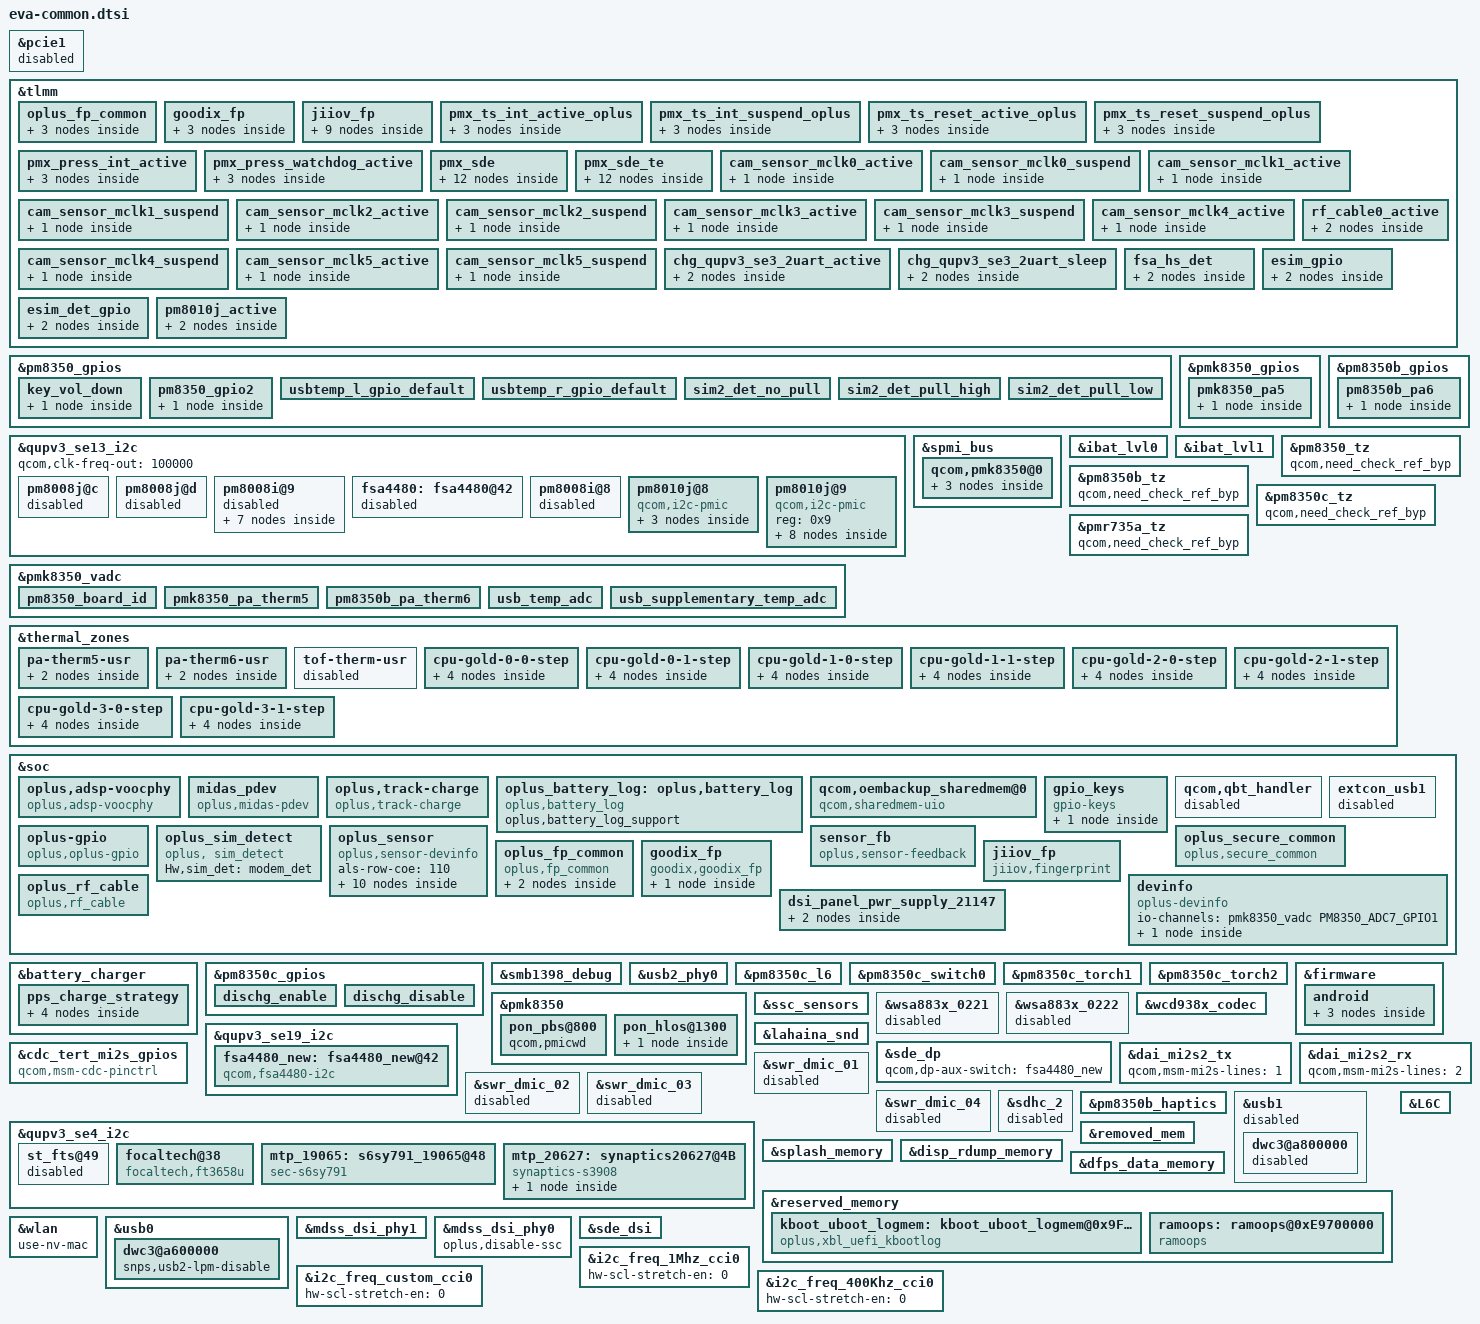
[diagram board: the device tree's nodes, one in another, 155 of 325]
//lahaina-pcie.dtsi
&pcie1 {
		status = "disabled";
		//#endif
};



//lahaina-pinctrl.dtsi

&tlmm {
	//#ifdef OPLUS_FEATURE_FINGERPRINT
	oplus_fp_common{
		gpio_id2_default: gpio_id2_default {
			mux {
				pins = "gpio119";
				function = "gpio";
			};
			config {
				pins = "gpio119";
				drive-strength = <2>;
				bias-pull-up;
				input-enable;
			};
		};
	};
	goodix_fp{
		gpio_goodix_irq_default: gpio_goodix_irq_default {
			mux {
				pins = "gpio38";
				function = "gpio";
			};
			config {
				pins = "gpio38";
				drive-strength = <2>;
				bias-disable;
				input-enable;
			};
		};
	};
	
	jiiov_fp{
		gpio_anc_reset_reset: gpio_anc_reset_reset {
			mux {
				pins = "gpio28";
				function = "gpio";
			};
			config {
				pins = "gpio28";
				drive-strength = <2>;
				bias-disable;
				output-low;
			};
		};
		gpio_anc_reset_active: gpio_anc_reset_active {
			mux {
				pins = "gpio28";
				function = "gpio";
			};
			config {
				pins = "gpio28";
				drive-strength = <2>;
				bias-disable;
				output-high;
			};
		};
		gpio_anc_irq_active: gpio_anc_irq_active {
			mux {
				pins = "gpio38";
				function = "gpio";
			};
			config {
				pins = "gpio38";
				drive-strength = <2>;
				bias-pull-down;
			};
		};
	};
	//#endif /*OPLUS_FEATURE_FINGERPRINT*/

	/* add pingrp for touchscreen */
	pmx_ts_int_active_oplus {
		ts_int_active: ts_int_active {
			mux {
				pins = "gpio23";
				function = "gpio";
			};

			config {
				pins = "gpio23";
				drive-strength = <8>;
				bias-disable;
				input-enable;
			};
		};
	};

	pmx_ts_int_suspend_oplus {
		ts_int_suspend1: ts_int_suspend1 {
			mux {
				pins = "gpio23";
				function = "gpio";
			};

			config {
				pins = "gpio23";
				drive-strength = <8>;
				//bias-pull-down;
				bias-pull-up;
				input-enable;
			};
		};
	};

	pmx_ts_reset_active_oplus {
		ts_reset_active: ts_reset_active {
			mux {
				pins = "gpio22";
				function = "gpio";
			};

			config {
				pins = "gpio22";
				drive-strength = <8>;
				output-low;
				bias-disable;
			};
		};
	};

	pmx_ts_reset_suspend_oplus {
		ts_reset_suspend1: ts_reset_suspend1 {
			mux {
				pins = "gpio22";
				function = "gpio";
			};

			config {
				pins = "gpio22";
				drive-strength = <2>;
				bias-pull-down;
			};
		};
	};
	//#endif


	pmx_press_int_active {
		press_int_active: press_int_active {
			mux {
				pins = "gpio51";
				function = "gpio";
			};

			config {
				pins = "gpio51";
				drive-strength = <2>;
				bias-disable;
				input-enable;
			};
		};
	};

	pmx_press_watchdog_active {
		watchdog_active: watchdog_active {
			mux {
				pins = "gpio97";
				function = "gpio";
			};

			config {
				pins = "gpio97";
				drive-strength = <2>;
				bias-disable;
				output-high;
			};
		};
	};
	//#endif

	pmx_sde: pmx_sde {
		sde_dsi_active: sde_dsi_active {
			mux {
				pins = "gpio24";
				function = "gpio";
			};

			config {
				pins = "gpio24";
				drive-strength = <8>;   /* 8 mA */
				bias-disable = <0>;   /* no pull */
			};
		};

		sde_dsi_suspend: sde_dsi_suspend {
			mux {
				pins = "gpio24";
				function = "gpio";
			};

			config {
				pins = "gpio24";
				drive-strength = <2>;   /* 2 mA */
				bias-pull-down;         /* PULL DOWN */
			};
		};

		sde_dsi1_active: sde_dsi1_active {
			mux {
				pins = "gpio25";
				function = "gpio";
			};

			config {
				pins = "gpio25";
				drive-strength = <8>;   /* 8 mA */
				bias-disable = <0>;   /* no pull */
			};
		};

		sde_dsi1_suspend: sde_dsi1_suspend {
			mux {
				pins = "gpio25";
				function = "gpio";
			};

			config {
				pins = "gpio25";
				drive-strength = <2>;   /* 2 mA */
				bias-pull-down;         /* PULL DOWN */
			};
		};
	};

	pmx_sde_te: pmx_sde_te {
		sde_te_active: sde_te_active {
			mux {
				pins = "gpio82";
				function = "mdp_vsync";
			};

			config {
				pins = "gpio82";
				drive-strength = <2>;   /* 2 mA */
				bias-pull-down;         /* PULL DOWN */
			};
		};

		sde_te_suspend: sde_te_suspend {
			mux {
				pins = "gpio82";
				function = "mdp_vsync";
			};

			config {
				pins = "gpio82";
				drive-strength = <2>;   /* 2 mA */
				bias-pull-down;         /* PULL DOWN */
			};
		};

		sde_te1_active: sde_te1_active {
			mux {
				pins = "gpio83";
				function = "mdp_vsync";
			};

			config {
				pins = "gpio83";
				drive-strength = <2>;   /* 2 mA */
				bias-pull-down;         /* PULL DOWN */
			};
		};

		sde_te1_suspend: sde_te1_suspend {
			mux {
				pins = "gpio83";
				function = "mdp_vsync";
			};

			config {
				pins = "gpio83";
				drive-strength = <2>;   /* 2 mA */
				bias-pull-down;         /* PULL DOWN */
			};
		};
	};
	//#endif
	cam_sensor_mclk0_active {

		config {
			/* #ifdef OPLUS_FEATURE_CAMERA_COMMON */
			drive-strength = <4>; /* 6 MA */
			/* #else */
			// drive-strength = <2>; /* 2 MA */
			/* #endif */
		};
	};
	cam_sensor_mclk0_suspend {

		config {
			/* #ifdef OPLUS_FEATURE_CAMERA_COMMON */
			drive-strength = <4>; /* 6 MA */
			/* #else */
			// drive-strength = <2>; /* 2 MA */
			/* #endif */
		};
	};

	cam_sensor_mclk1_active {

		config {
			/* #ifdef OPLUS_FEATURE_CAMERA_COMMON */
			drive-strength = <4>; /* 4 MA */
			/* #else */
			// drive-strength = <2>; /* 2 MA */
			/* #endif */
		};
	};


	cam_sensor_mclk1_suspend {

		config {
			/* #ifdef OPLUS_FEATURE_CAMERA_COMMON */
			drive-strength = <4>; /* 4 MA */
			/* #else */
			// drive-strength = <2>; /* 2 MA */
			/* #endif */
		};
	};

	cam_sensor_mclk2_active {

		config {
			/* #ifdef OPLUS_FEATURE_CAMERA_COMMON */
			drive-strength = <6>; /* 6 MA */
			/* #else */
			// drive-strength = <2>; /* 2 MA */
			/* #endif */
		};
	};

	cam_sensor_mclk2_suspend {

		config {
			/* #ifdef OPLUS_FEATURE_CAMERA_COMMON */
			drive-strength = <6>; /* 6 MA */
			/* #else */
			// drive-strength = <2>; /* 2 MA */
			/* #endif */
		};
	};

	cam_sensor_mclk3_active {

		config {
			/* #ifdef OPLUS_FEATURE_CAMERA_COMMON */
			drive-strength = <6>; /* 6 MA */
			/* #else */
			// drive-strength = <2>; /* 2 MA */
			/* #endif */
		};
	};

	cam_sensor_mclk3_suspend {

		config {
			/* #ifdef OPLUS_FEATURE_CAMERA_COMMON */
			drive-strength = <6>; /* 6 MA */
			/* #else */
			// drive-strength = <2>; /* 2 MA */
			/* #endif */
		};
	};

	cam_sensor_mclk4_active {

		config {
			/* #ifdef OPLUS_FEATURE_CAMERA_COMMON */
			drive-strength = <6>; /* 6 MA */
			/* #else */
			// drive-strength = <2>; /* 2 MA */
			/* #endif */
		};
	};

	cam_sensor_mclk4_suspend {

		config {
			/* #ifdef OPLUS_FEATURE_CAMERA_COMMON */
			drive-strength = <6>; /* 6 MA */
			/* #else */
			// drive-strength = <2>; /* 2 MA */
			/* #endif */
		};
	};

	cam_sensor_mclk5_active {

		config {
			/* #ifdef OPLUS_FEATURE_CAMERA_COMMON */
			drive-strength = <6>; /* 6 MA */
			/* #else */
			// drive-strength = <2>; /* 2 MA */
			/* #endif */
		};
	};

	cam_sensor_mclk5_suspend {

		config {
			/* #ifdef OPLUS_FEATURE_CAMERA_COMMON */
			drive-strength = <6>; /* 6 MA */
			/* #else */
			// drive-strength = <2>; /* 2 MA */
			/* #endif */
		};
	};

	rf_cable0_active: rf_cable0_active {
		mux {
			pins = "gpio99";
			function = "gpio";
		};
		config {
			pins = "gpio99";
			drive-strength = <2>;
			input-enable;
			bias-pull-up;
		};
	};
};



//lahaina-pmic-overlay.dtsi
&pm8350_gpios {
	///delete-node/ key_vol_up;
//#else
	key_vol_down {
		key_vol_down_default: key_vol_down_default {
			pins = "gpio6";
			function = "normal";
			input-enable;
			bias-pull-up;
			power-source = <1>;
		};
	};
//#endif
};

&qupv3_se13_i2c {
	pm8008j@c {
		status = "disabled";
	};

	pm8008j@d {
		status = "disabled";
	};

	pm8008i@9 {

		qcom,pm8008i-regulator {
			vdd_l3_l4-supply = <&BOB>;
			//vdd_l3_l4-supply = <&S1C>;
			vdd_l5-supply = <&BOB>;
/*endif*/


			//L2I: pm8008i_l2: regulator@4100 {
			regulator@4100 {
				reg = <0x4100>;
				regulator-name = "pm8008i_l2";
				regulator-min-microvolt = <944000>;
				regulator-max-microvolt = <1256000>;
/*endif*/
				qcom,min-dropout-voltage = <150000>;
				qcom,hpm-min-load = <30000>;
			};

			//L3I: pm8008i_l3: regulator@4200 {
			regulator@4200 {
				reg = <0x4200>;
				regulator-name = "pm8008i_l3";
				regulator-min-microvolt = <1500000>;
				//regulator-min-microvolt = <1696000>;
				regulator-max-microvolt = <1800000>;
				qcom,min-dropout-voltage = <70000>;
/*endif*/
			};

			//L4I: pm8008i_l4: regulator@4300 {
			regulator@4300 {
				reg = <0x4300>;
				regulator-name = "pm8008i_l4";
				regulator-min-microvolt = <1696000>;
				regulator-max-microvolt = <1800000>;
				qcom,min-dropout-voltage = <70000>;
/*endif*/
			};

			//L5I: pm8008i_l5: regulator@4400 {
			regulator@4400 {
				reg = <0x4400>;
				regulator-name = "pm8008i_l5";
				regulator-min-microvolt = <2696000>;
				regulator-max-microvolt = <3000000>;
				qcom,min-dropout-voltage = <200000>;
/*endif*/
			};

			//L6I: pm8008i_l6: regulator@4500 {
			regulator@4500 {
				reg = <0x4500>;
				regulator-name = "pm8008i_l6";
				regulator-min-microvolt = <2696000>;
				regulator-max-microvolt = <3000000>;
/*endif*/
				qcom,min-dropout-voltage = <200000>;
			};

			//L7I: pm8008i_l7: regulator@4600 {
			regulator@4600 {
				reg = <0x4600>;
				regulator-name = "pm8008i_l7";
				regulator-min-microvolt = <2696000>;
				regulator-max-microvolt = <3000000>;
				qcom,min-dropout-voltage = <200000>;
			};
		};
	};

};



&pm8350_gpios {

	pm8350_gpio2 {
		pm8350_gpio2_default: pm8350_gpio2_default {
			pins = "gpio2";
			bias-high-impedance;
		};
	};
};

&pmk8350_gpios {
	pmk8350_pa5 {
		pmk8350_pa5_therm_default: pmk8350_pa5_therm_default {
			pins = "gpio3";
			bias-high-impedance;
		};
	};

};

&pm8350b_gpios {
	pm8350b_pa6 {
		pm8350b_pa6_therm_default: pm8350b_pa6_therm_default {
			pins = "gpio1";
			bias-high-impedance;
		};
	};

};

&spmi_bus {
	qcom,pmk8350@0 {
		pm8350_adc_tm_iio: adc_tm_iio@3400 {
			/* Alternate ADC_TM DT node */
			compatible = "qcom,adc-tm7-iio";
			/* With this entry, a feature-reduced
			version of the driver is initialized (only
			thermistor reads, no interrupt functionality
			for exposed thermistors) */
			reg = <0x3400>;
			#thermal-sensor-cells = <1>;
			#address-cells = <1>;
			#size-cells = <0>;
			io-channels = <&pmk8350_vadc PM8350B_ADC7_GPIO1_100K_PU>,
				      <&pmk8350_vadc PMK8350_ADC7_AMUX_THM4_100K_PU>;
			/* Similar to io-channels in actual ADC_TM node,
			for reading thermistor temperature from
			VADC */

			pm8350b_pa_therm6 {
				/* ADC_TM child node, similar to previous */
				reg = <PM8350B_ADC7_GPIO1_100K_PU>;
				qcom,ratiometric;
				qcom,hw-settle-time = <200>;
			};
			pmk8350_pa_therm5 {
				/* ADC_TM child node, similar to previous */
				reg = <PMK8350_ADC7_AMUX_THM4_100K_PU>;
				qcom,ratiometric;
				qcom,hw-settle-time = <200>;
			};

		};
	};
};

&pmk8350_vadc {
	pinctrl-names = "default";
	//pinctrl-0 = <&pm8350_rear_tof_therm_default>;
//#else
	pinctrl-0 = <&pm8350_gpio2_default &pmk8350_pa5_therm_default &pm8350b_pa6_therm_default>;

	pm8350_board_id {
		reg = <PM8350_ADC7_GPIO1>;
		label = "pm8350_board_id";
		//qcom,ratiometric;
		qcom,hw-settle-time = <200>;
		qcom,pre-scaling = <1 1>;
	};

	pmk8350_pa_therm5 {
		reg = <PMK8350_ADC7_AMUX_THM4_100K_PU>;
		label = "pmk8350_pa_therm5";
		qcom,ratiometric;
		qcom,hw-settle-time = <200>;
		qcom,pre-scaling = <1 1>;
	};

	pm8350b_pa_therm6 {
		reg = <PM8350B_ADC7_GPIO1_100K_PU>;
		label = "pm8350b_pa_therm6";
		qcom,ratiometric;
		qcom,hw-settle-time = <200>;
		qcom,pre-scaling = <1 1>;
	};
};

&ibat_lvl0 {
	temperature = <7500>;
	hysteresis = <200>;
	type = "passive";
};
&ibat_lvl1 {
	temperature = <10000>;
	hysteresis = <200>;
	type = "passive";
};

//#ifdef OPLUS_FEATURE_CHG_BASIC
&pm8350_tz {
	qcom,need_check_ref_byp;
};

&pm8350b_tz {
	qcom,need_check_ref_byp;
};

&pm8350c_tz {
	qcom,need_check_ref_byp;
};

&pmr735a_tz {
	qcom,need_check_ref_byp;
};
//#endif

&thermal_zones {
	pa-therm5-usr {
		polling-delay-passive = <0>;
		polling-delay = <0>;
		thermal-governor = "user_space";
		thermal-sensors = <&pm8350_adc_tm_iio PMK8350_ADC7_AMUX_THM4_100K_PU>;
		/* phandle and channel number of added channel */
		wake-capable-sensor;
		trips {
			active-config0 {
				temperature = <55000>;
				hysteresis = <1000>;
				type = "passive";
			};
		};
	};

	pa-therm6-usr {
		polling-delay-passive = <0>;
		polling-delay = <0>;
		thermal-governor = "user_space";
		thermal-sensors = <&pm8350_adc_tm_iio PM8350B_ADC7_GPIO1_100K_PU>;
		/* phandle and channel number of added channel */
		wake-capable-sensor;
		trips {
			active-config0 {
				temperature = <55000>;
				hysteresis = <1000>;
				type = "passive";
			};
		};
	};
};

&soc {
	oplus,adsp-voocphy {
		compatible = "oplus,adsp-voocphy";
	};

	midas_pdev {
                compatible = "oplus,midas-pdev";
        };
};
&battery_charger {
	//for oplus chg framework:
	oplus,chg_ops = "plat-pmic";
	qcom,smart_charging_screenoff;
	qcom,input_current_charger_ma = <2000>;
	qcom,pd_input_current_charger_ma = <2000>;
	qcom,qc_input_current_charger_ma = <2000>;

	qcom,input_current_usb_ma = <500>;

	qcom,input_current_cdp_ma = <1500>;
	qcom,input_current_led_ma = <1200>;
	qcom,input_current_led_ma_high = <1800>;
	qcom,input_current_led_ma_warm = <1800>;
	qcom,input_current_led_ma_normal = <2000>;
	qcom,led_warm_bat_decidegc = <350>;
	qcom,led_high_bat_decidegc = <370>;

	qcom,input_current_camera_ma = <1200>;

	qcom,input_current_vooc_led_ma_high = <1800>;
	qcom,input_current_vooc_led_ma_warm = <1800>;
	qcom,input_current_vooc_led_ma_normal = <3600>;
	qcom,input_current_vooc_ma_normal = <3600>;
	qcom,vooc_temp_bat_normal_decidegc = <350>;
	qcom,input_current_vooc_ma_warm = <3200>;
	qcom,vooc_temp_bat_warm_decidegc = <370>;
	qcom,input_current_vooc_ma_high = <2200>;
	qcom,vooc_temp_bat_hot_decidegc = <440>;

	qcom,charger_current_vooc_ma_normal = <1800>;

	qcom,chg_ctrl_by_calling;
	qcom,input_current_calling_ma = <1500>;

	//qcom,input_current_led_ma_overtemp = <900>;
	qcom,overtemp_bat_decidegc = <350>;
	qcom,iterm_disabled = <0>;
	qcom,iterm_ma = <130>;
	qcom,recharge-mv = <100>;
	qcom,batt_capacity_mah = <5000>;/*typical capacity*/
	//qcom,batt_capacity_mah = <4400>; /*rated capacity*/

	qcom,removed_bat_decidegc = <190>;  /*<-19C*/

	qcom,cold_bat_decidegc = <100>;  /*-10C~0C*/
	qcom,temp_cold_vfloat_mv = <4435>;
	qcom,temp_cold_fastchg_current_ma = <600>;

	qcom,little_cold_bat_decidegc = <0>;	/*0C~5C*/
	qcom,temp_little_cold_vfloat_mv = <4435>;
	qcom,temp_little_cold_fastchg_current_ma_high = <1100>;
	qcom,temp_little_cold_fastchg_current_ma_low = <1100>;
	qcom,temp_little_cold_fastchg_current_ma = <1100>;
	qcom,pd_temp_little_cold_fastchg_current_ma_high = <2000>;
	qcom,pd_temp_little_cold_fastchg_current_ma_low = <1560>;
	qcom,qc_temp_little_cold_fastchg_current_ma_high = <2000>;
	qcom,qc_temp_little_cold_fastchg_current_ma_low = <1560>;

	qcom,cool_bat_decidegc = <50>;	/*5C~12C*/
	qcom,temp_cool_vfloat_mv = <4435>;
	qcom,temp_cool_fastchg_current_ma_high = <1100>;
	qcom,temp_cool_fastchg_current_ma_low = <1100>;
	qcom,pd_temp_cool_fastchg_current_ma_high = <2000>;
	qcom,pd_temp_cool_fastchg_current_ma_low = <2000>;
	qcom,qc_temp_cool_fastchg_current_ma_high = <2000>;
	qcom,qc_temp_cool_fastchg_current_ma_low = <2000>;

	qcom,little_cool_bat_decidegc = <120>;	/*12C~16C*/
	qcom,temp_little_cool_vfloat_mv = <4435>;
	qcom,temp_little_cool_fastchg_current_ma = <1100>;
	qcom,pd_temp_little_cool_fastchg_current_ma = <2000>;
	qcom,qc_temp_little_cool_fastchg_current_ma = <2000>;

	qcom,normal_bat_decidegc = <160>;	/*16C~44C*/
	qcom,temp_normal_fastchg_current_ma = <1100>;
	qcom,temp_normal_vfloat_mv = <4435>;
	qcom,pd_temp_normal_fastchg_current_ma = <2000>;
	qcom,qc_temp_normal_fastchg_current_ma = <2000>;

	qcom,warm_bat_decidegc = <450>;		/*45C~53C*/ /*8pin Bat Vooc project need add 3 degree C*/
	qcom,temp_warm_vfloat_mv = <4130>;
	qcom,temp_warm_fastchg_current_ma = <1100>;
	qcom,pd_temp_warm_fastchg_current_ma = <1200>;
	qcom,qc_temp_warm_fastchg_current_ma = <1200>;
	qcom,temp_warm_fastchg_current_ma_led_on = <500>;

	qcom,hot_bat_decidegc = <530>;

	qcom,non_standard_vfloat_mv = <3980>;
	qcom,non_standard_fastchg_current_ma = <512>;

	qcom,short_c_bat_cv_mv = <4330>;
	qcom,short_c_bat_vfloat_mv = <3800>;
	qcom,short_c_bat_fastchg_current_ma = <512>;

	qcom,cold_vfloat_sw_limit = <4385>;
	qcom,little_cold_vfloat_sw_limit = <4385>;
	qcom,cool_vfloat_sw_limit = <4385>;
	qcom,little_cool_vfloat_sw_limit = <4385>;
	qcom,normal_vfloat_sw_limit = <4385>;
	qcom,warm_vfloat_sw_limit = <4080>;
	qcom,non_standard_vfloat_sw_limit = <3930>;
	qcom,short_c_bat_vfloat_sw_limit = <3750>;

	qcom,max_chg_time_sec = <36000>;
	qcom,charger_hv_thr = <9900>;
	qcom,charger_recv_thr = <9500>;
	qcom,charger_lv_thr = <3400>;
	qcom,vbatt_full_thr = <4435>;
	qcom,vbatt_hv_thr = <4600>;
	qcom,vfloat_step_mv = <8>;
	qcom,non_standard_vfloat_over_sw_limit = <3990>;
	qcom,cold_vfloat_over_sw_limit = <4445>;
	qcom,little_cold_vfloat_over_sw_limit = <4445>;
	qcom,cool_vfloat_over_sw_limit = <4445>;
	qcom,little_cool_vfloat_over_sw_limit = <4445>;
	qcom,normal_vfloat_over_sw_limit = <4445>;
	qcom,warm_vfloat_over_sw_limit = <4140>;

	qcom,vbatt_power_off = <3300>;
	qcom,vbatt_soc_1 = <3310>;
	qcom,vooc_project = <7>;
	qcom,vbatt_num = <2>;
	qcom,ffc_support;
	qcom,dual_ffc;
	//recharge_after_full;
	//qcom,wireless_support;
	//qcom,wpc_no_chargerpump;
	qcom,voocphy_support = <1>;
	qcom,fg_info_package_read_support;

	qcom,normal_vterm_hw_inc = <18>;
	qcom,non_normal_vterm_hw_inc = <18>;

	qcom,ff1_normal_fastchg_ma = <550>;
	qcom,ff1_warm_fastchg_ma = <550>;
	qcom,ffc2_normal_fastchg_ma = <350>;/*12C~35c*/
	qcom,ffc2_temp_warm_decidegc = <350>;
	qcom,ffc2_warm_fastchg_ma = <400>;/*35C~40c*/
	qcom,ffc2_temp_high_decidegc = <400>;
	qcom,ffc2_temp_low_decidegc = <120>;
	qcom,ffc2_exit_step_ma = <100>;
	qcom,ff1_exit_step_ma = <150>;
	qcom,ff1_warm_exit_step_ma = <150>;

	qcom,ffc_normal_vfloat_sw_limit = <4445>;
	qcom,ffc2_normal_vfloat_sw_limit = <4440>;
	qcom,ffc2_warm_vfloat_sw_limit = <4440>;
	qcom,ffc_temp_normal_vfloat_mv = <4500>;
	qcom,ffc1_temp_normal_vfloat_mv = <4500>;
	qcom,ffc2_temp_normal_vfloat_mv = <4500>;
	qcom,ffc_normal_vfloat_over_sw_limit = <4500>;
	qcom,ffc1_normal_vfloat_over_sw_limit = <4500>;
	qcom,ffc2_normal_vfloat_over_sw_limit = <4500>;

	qcom,default_iterm_ma = <130>;
	qcom,default_temp_normal_fastchg_current_ma = <1100>;
	qcom,default_normal_vfloat_sw_limit = <4385>;
	qcom,default_temp_normal_vfloat_mv = <4435>;
	qcom,default_normal_vfloat_over_sw_limit = <4445>;

	qcom,default_temp_little_cool_fastchg_current_ma = <1100>;
	qcom,default_little_cool_vfloat_sw_limit = <4385>;
	qcom,default_temp_little_cool_vfloat_mv = <4435>;
	qcom,default_little_cool_vfloat_over_sw_limit = <4445>;

	qcom,pps_support_type = <0>;

	qcom,pps_multistep_initial_batt_temp = <310>;
	qcom,pps_strategy_normal_power = <6000>;//6A
	qcom,pps-normal-to-little-cool-power = <5000>;//5A
	qcom,pps_batt_over_high_temp = <440>;
	qcom,pps_batt_over_low_temp = <50>;
	qcom,pps_over_high_or_low_power = <3000>;

	qcom,pps_strategy1_batt_high_temp0 = <425>;
	qcom,pps_strategy1_batt_high_temp1 = <430>;
	qcom,pps_strategy1_batt_high_temp2 = <435>;
	qcom,pps_strategy1_batt_low_temp2 = <420>;
	qcom,pps_strategy1_batt_low_temp1 = <415>;
	qcom,pps_strategy1_batt_low_temp0 = <400>;

	qcom,pps_strategy1_high_power0 = <4000>;//4A
	qcom,pps_strategy1_high_power1 = <4000>;//4A
	qcom,pps_strategy1_high_power2 = <3000>;//3A
	qcom,pps_strategy1_low_power2 = <3000>;//3A
	qcom,pps_strategy1_low_power1 = <4000>;//4A
	qcom,pps_strategy1_low_power0 = <4000>;//4A

	/* batt_curr, usbtemp_r, timeout */
	temp_curr_monitor_table = <5000 64 30000>;

	///qcom,offset_temp = <30>;
	//for control:
	//qcom,suspend_after_full;
	qcom,check_batt_full_by_sw;
	qcom,external_gauge;
	qcom,chg_ctrl_by_lcd;
	qcom,chg_ctrl_by_vooc;
	qcom,chg_ctrl_by_camera;
	qcom,sw_vfloat_over_protect_enable;
	qcom,support_tbatt_shell;
	qcom,usbtemp_batttemp_gap = <14>;

	//for PD9V or QC9V
	//qcom,vbatt_pdqc_to_5v_thr = <4100>;
	qcom,vbatt_pdqc_to_9v_thr = <5000>;/*always 9v*/
	qcom,vooc_show_ui_soc_decimal;
	qcom,ui_soc_decimal_speedmin = <20>;//2A
	qcom,otg_scheme = <0>;//0:cid 1:ccdetect_gpio 2:switch
	//qcom,soft_aicl_in_adsp_support;

	qcom,dischg-gpio = <&pm8350c_gpios 9 0x00>;
	pinctrl-names = "usbtemp_l_gpio_default", "usbtemp_r_gpio_default",
			"dischg_enable", "dischg_disable",
			"chg_qupv3_se3_2uart_active", "chg_qupv3_se3_2uart_sleep";

	pinctrl-0 = <&usbtemp_l_gpio_default>;
	pinctrl-1 = <&usbtemp_r_gpio_default>;
	pinctrl-2 = <&dischg_enable>;
	pinctrl-3 = <&dischg_disable>;
	pinctrl-4 = <&chg_qupv3_se3_2uart_active>;
	pinctrl-5 = <&chg_qupv3_se3_2uart_sleep>;

/*	qcom,vooc_vbus_adc-gpio = <&pm8350c_gpios 8 0x00>;
	qcom,ship-gpio = <&tlmm 29 0x00>;

	pinctrl-names = "vooc_vbus_adc_active", "vooc_vbus_adc_sleep",
					"ship_active", "ship_sleep";

	pinctrl-0 = <&vooc_vbus_adc_active>;
	pinctrl-1 = <&vooc_vbus_adc_sleep>;
	pinctrl-2 = <&ship_active>;
	pinctrl-3 = <&ship_sleep>;

	qcom,chargerid_switch-gpio = <&tlmm 7 0x00>;
	qcom,ship-gpio = <&tlmm 6 0x00>;
	//qcom,ccdetect-gpio = <&tlmm 14 0x00>;
	//qcom,shortc-gpio = <&tlmm 43 0x00>;
	qcom,dischg-gpio = <&pm8350c_gpios 9 0x00>;
	//qcom,charger_int-gpio = <&tlmm 15 0x00>;
	//qcom,input_pg-gpio = <&tlmm 6 0x00>;
	//qcom,charger_error-gpio = <&tlmm 118 0x00>;

	qcom,idt_en-gpio = <&pm8150_gpios 10 0x00>;
	qcom,wrx_en-gpio = <&pm8150l_gpios 8 0x00>;
	qcom,wrx_otg-gpio = <&pm8150l_gpios 11 0x00>;

	pinctrl-names = "default",
					"chargerid_switch_active", "chargerid_switch_sleep", "chargerid_switch_default",
					"ship_active", "ship_sleep",
					"ccdetect_active", "ccdetect_sleep",
					"dischg_enable", "dischg_disable",
					"gpio1_adc_default","gpio8_adc_default","gpio5_adc_default",
					"charger_int_default",
					"input_pg_default",
					"charger_error_default",
					"idt_en_active", "idt_en_sleep", "idt_en_default",
					"wrx_en_active", "wrx_en_sleep", "wrx_en_default",
					"wrx_otg_active", "wrx_otg_sleep";

	pinctrl-0 = <&gpio7_adc_default>;
	pinctrl-1 = <&chargerid_switch_active>;
	pinctrl-2 = <&chargerid_switch_sleep>;
	pinctrl-3 = <&chargerid_switch_default>;
	pinctrl-4 = <&ship_active>;
	pinctrl-5 = <&ship_sleep>;
	pinctrl-6 = <&ccdetect_active>;
	pinctrl-7 = <&ccdetect_sleep>;
	pinctrl-8 = <&dischg_enable>;
	pinctrl-9 = <&dischg_disable>;
	pinctrl-10 = <&gpio1_adc_default>;
	pinctrl-11 = <&gpio8_adc_default>;
	pinctrl-12 = <&gpio5_adc_default>;
	pinctrl-13 = <&charger_int_default>;
	pinctrl-14 = <&input_pg_default>;
	pinctrl-15 = <&charger_error_default>;

	pinctrl-16 = <&idt_en_active>;
	pinctrl-17 = <&idt_en_sleep>;
	pinctrl-18 = <&idt_en_default>;
	pinctrl-19 = <&wrx_en_active>;
	pinctrl-20 = <&wrx_en_sleep>;
	pinctrl-21 = <&wrx_en_default>;
	pinctrl-22 = <&wrx_otg_active>;
	pinctrl-23 = <&wrx_otg_sleep>;
*/
	pps_charge_strategy {
		strategy_soc_0_to_50 {
			strategy_temp_0_to_50 =		<10000 4180 2000 0 0
							 10000 4420 1400 0 0
							 10000 4430 1000 1 0>;
			strategy_temp_50_to_120 =	<10000 4180 2400 0 0
							 10000 4180 2000 0 0
							 10000 4180 1500 0 0
							 10000 4430 1000 1 0>;
			strategy_temp_120_to_160 = 	<10000 4420 3000 0 0
							 10000 4420 2500 0 0
							 10000 4420 2000 0 0
							 10000 4420 1500 0 0
							 10000 4430 1000 1 0>;
			strategy_temp_160_to_430 =	<10000 4420 3000 0 0
							 10000 4420 2500 0 0
							 10000 4420 2000 0 0
							 10000 4420 1500 0 0
							 10000 4430 1000 1 0>;
		};

		strategy_soc_50_to_75 {
			strategy_temp_0_to_50 =		<10000 4180 2000 0 0
							 10000 4420 1500 0 0
							 10000 4430 1000 1 0>;
			strategy_temp_50_to_120 =	<10000 4180 2500 0 0
							 10000 4180 2000 0 0
							 10000 4180 1500 0 0
							 10000 4430 1000 1 0>;
			strategy_temp_120_to_160 =	<10000 4420 2500 0 0
							 10000 4420 2000 0 0
							 10000 4420 1500 0 0
							 10000 4430 1000 1 0>;
			strategy_temp_160_to_430 =	<10000 4420 3000 0 0
							 10000 4420 2500 0 0
							 10000 4420 2000 0 0
							 10000 4420 1500 0 0
							 10000 4430 1000 1 0>;
		};

		strategy_soc_75_to_85 {
			strategy_temp_0_to_50 = 	<10000 4420 1500 0 0
							 10000 4430 1000 1 0>;
			strategy_temp_50_to_120 =	<10000 4180 2000 0 0
							 10000 4180 1500 0 0
							 10000 4430 1000 1 0>;
			strategy_temp_120_to_160 =	<10000 4420 2000 0 0
							 10000 4420 1500 0 0
							 10000 4430 1000 1 0>;
			strategy_temp_160_to_430 =	<10000 4420 2000 0 0
							 10000 4420 1500 0 0
							 10000 4430 1000 1 0>;
		};

		strategy_soc_85_to_90 {
			strategy_temp_0_to_50 = 	<10000 4430 1000 1 0>;
			strategy_temp_50_to_120 =	<10000 4430 1000 1 0>;
			strategy_temp_120_to_160 =	<10000 4420 1500 0 0
							 10000 4430 1000 1 0>;
			strategy_temp_160_to_430 =	<10000 4420 1500 0 0
							 10000 4430 1000 1 0>;
		};
	};
};

&pm8350_gpios {
	/delete-node/ pm8350_rear_tof_therm_default;
	usbtemp_l_gpio_default: usbtemp_l_gpio_default {
		pins = "gpio1"; /* GPIO 1 */
		function = "normal"; /* normal */
		bias-high-impedance; /* DISABLE GPIO1 for ADC*/
    };
	usbtemp_r_gpio_default: usbtemp_r_gpio_default {
        pins = "gpio3"; /* GPIO 3 */
		function = "normal"; /* normal */
        bias-high-impedance; /* DISABLE GPIO3 for ADC*/
    };
};

&pmk8350_vadc {
	/delete-node/ pm8350_rear_tof_therm;
	usb_temp_adc {
		reg = <PM8350_ADC7_AMUX_THM5_100K_PU>;
		label = "usb_temp_adc";
		qcom,pre-scaling = <1 1>;
		qcom,ratiometric;
		qcom,hw-settle-time = <200>;
	};
	usb_supplementary_temp_adc {
		reg = <PM8350_ADC7_GPIO2_100K_PU>;
		label = "usb_supplementary_temp_adc";
		qcom,pre-scaling = <1 1>;
		qcom,ratiometric;
		qcom,hw-settle-time = <200>;
	};
};

&battery_charger {
	io-channels	= <&pmk8350_vadc PM8350_ADC7_AMUX_THM5_100K_PU>,
					<&pmk8350_vadc PM8350_ADC7_GPIO2_100K_PU>;
	io-channel-names = "usb_temp_adc",
						"usb_supplementary_temp_adc";
};

&pm8350c_gpios {
	dischg_enable: dischg_enable {
		pins = "gpio9"; /* GPIO 9 */
		function = "normal"; /* normal */
		bias-disable; //No Pull
		power-source = <0>;//VIN0 3.3
		output-high; //digital output, no invert
		qcom,drive-strength = <3>; //LOW strength
		//drive-push-pull;//CMOS
	};

	dischg_disable: dischg_disable {
		pins = "gpio9"; /* GPIO 9 */
		function = "normal"; /* normal */
		bias-disable; //No Pull
		power-source = <0>;//VIN0 3.3
		output-low; //digital output, no invert
		qcom,drive-strength = <3>; //LOW strength
		//drive-push-pull;//CMOS
	};
};
/*&pm8350c_gpios {
	vooc_vbus_adc_active: vooc_vbus_adc_active {
		pins = "gpio8";
		function = "normal";
		qcom,drive-strength = <2>;
		power-source = <1>;
		bias-pull-up;
		output-high;
	};

	vooc_vbus_adc_sleep: vooc_vbus_adc_sleep {
		pins = "gpio8";
		function = "normal";
		qcom,drive-strength = <2>;
		power-source = <1>;
		bias-pull-down;
		output-low;
	};
};*/

&tlmm {
	chg_qupv3_se3_2uart_active: chg_qupv3_se3_2uart_active {
		mux {
			pins = "gpio18", "gpio19";
			function = "qup3";
		};

		config {
			pins = "gpio18", "gpio19";
			drive-strength = <2>;
			bias-disable;
		};
	};

	chg_qupv3_se3_2uart_sleep: chg_qupv3_se3_2uart_sleep {
		mux {
			pins = "gpio18", "gpio19";
			function = "gpio";
		};

		config {
			pins = "gpio18", "gpio19";
			drive-strength = <2>;
			input-enable;
			bias-pull-down;
		};
	};

	/*ship_sleep: ship_sleep {
		mux {
			pins = "gpio29";
			function = "gpio";
		};

		config {
			pins = "gpio29";
			drive-strength = <2>;
			bias-pull-down;
			output-low;
		};
	};

	ship_active: ship_active {
		mux {
			pins = "gpio29";
			function = "gpio";
		};

		config {
			pins = "gpio29";
			drive-strength = <2>;
			bias-pull-up;
			output-high;
		};
	};*/
};

&smb1398_debug {
	status = "ok";
};

&usb2_phy0 {
	qcom,param-override-seq =
			<0x63 0x6c	/* override_x0 */
			 0x0f 0x70	/* override_x1 */
			 0x17 0x74>;	/* override x2 */

        qcom,param-override-seq-host =
                        <0xe7 0x6c      /* override_x0 */
                         0x0c 0x70      /* override_x1 */
                         0x17 0x74>;    /* override x2 */
};

&soc {
	oplus,track-charge {
		compatible = "oplus,track-charge";
		track,fast_chg_break_t_thd = <1000>;
		track,general_chg_break_t_thd = <200>;
		track,voocphy_type = <1>;
		track,wls_max_power = <0>;
		track,wired_max_power = <80000>;
		track,wls_bpp_chg_scheme = <0>;
		track,wls_epp_chg_scheme = <0>;
		track,wls_fast_chg_scheme = <0>;
		track,wired_fast_chg_scheme = <1>;
	};

	oplus_battery_log: oplus,battery_log {
		compatible = "oplus,battery_log";
		oplus,battery_log_support;
	};
};
//#endif /*OPLUS_FEATURE_CHG_BASIC*/



//#lahaina-qupv3.dtsi
//#ifdef OPLUS_FEATRUE_ESIM
/*
&qupv3_se0_spi {
	status = "disabled";
};
*/
//#endif /* OPLUS_FEATRUE_ESIM */

//#ifdef OPLUS_FEATRUE_ESIM
/*
&qupv3_se10_spi {
		status = "disabled";
};
*/
//#endif /* OPLUS_FEATRUE_ESIM */


//lahaina-regulators.dtsi
&pm8350c_l6 {
	/delete-property/ qcom,proxy-consumer-enable;
	/delete-property/ qcom,proxy-consumer-current;
};


//pm8350c.dtsi
&pm8350c_switch0 {
	qcom,led-mask = <1>; /* Channels 1 & 4 */
	qcom,symmetry-en;
};

&pm8350c_torch1 {
/*#ifdef OPLUS_FEATURE_CAMERA_COMMON*/
				qcom,max-current-ma = <25>;
				qcom,ires-ua = <5000>;
/*#endif*/
};
&pm8350c_torch2 {
/*#ifdef OPLUS_FEATURE_CAMERA_COMMON*/
				qcom,max-current-ma = <25>;
				qcom,ires-ua = <5000>;
/*#endif*/
};


//pmk8350.dtsi
&pmk8350 {
	pon_pbs@800 {
		//#ifdef OPLUS_FEATURE_QCOM_PMICWD
		qcom,pmicwd;
		//#endif /* OPLUS_FEATURE_QCOM_PMICWD */
	};
  
	pon_hlos@1300 {
			/*qcom,pon_2 {
				qcom,pon-type = <PON_POWER_ON_TYPE_RESIN>;
				linux,code = <KEY_VOLUMEDOWN>;
			};*/
			//#else
			reg = <0x1300>, <0x800>;
			reg-names = "pon_hlos", "pon_pbs";
			qcom,kpdpwr-sw-debounce;
			qcom,pon_2 {
				qcom,pon-type = <PON_POWER_ON_TYPE_RESIN>;
				linux,code = <KEY_VOLUMEUP>;
			};
			//#endif
	};
};

//lahaina.dtsi
&firmware {
		android {
			vbmeta {
				parts = "vbmeta,boot,system,vendor,dtbo,vendor_boot";
				//#else
				//parts = "vbmeta,boot,system,vendor,dtbo,recovery";
			};

			fstab {
				vendor {
					fsmgr_flags = "wait,slotselect,avb";
//#else
					//fsmgr_flags = "wait,avb";
				};
			};
		};
};


&soc {
	//#ifdef FEATURE_OPLUS_NV_BACKUP
	//add for creating a shared memory with uio for nv backup and restore
	qcom,oembackup_sharedmem@0 {
		compatible = "qcom,sharedmem-uio";
		reg = <0x0 0x280000>;
		reg-names = "oembackup";
		qcom,client-id = <0x00000004>;
	};
	//#endif /* FEATURE_OPLUS_NV_BACKUP */
};
&ssc_sensors {
		vdd-supply = <&pm8350c_l7>;
		vddio-supply = <&pm8350c_l8>;
//#endif
};



//lahaina-audio-overlay.dtsi
&wsa883x_0221 {
	status = "disabled";
};

&wsa883x_0222 {
	status = "disabled";
};

&wcd938x_codec {
		//qcom,cdc-micbias2-mv = <1800>;
/* #else */
	qcom,cdc-micbias1-mv = <2700>;
	qcom,cdc-micbias2-mv = <2700>;
	qcom,cdc-micbias3-mv = <2700>;
};

&lahaina_snd {
	qcom,audio-routing =
		"AMIC1", "Analog Mic1",
		"Analog Mic1", "MIC BIAS1",
		"AMIC2", "Analog Mic2",
		"Analog Mic2", "MIC BIAS2",
		"AMIC3", "Analog Mic3",
		"Analog Mic3", "MIC BIAS3",
		"AMIC4", "Analog Mic4",
		"Analog Mic4", "MIC BIAS3",
		"AMIC5", "Analog Mic5",
		"Analog Mic5", "MIC BIAS3",
		"TX DMIC0", "Digital Mic0",
		"TX DMIC0", "MIC BIAS3",
		"TX DMIC1", "Digital Mic1",
		//"TX DMIC1", "MIC BIAS3",
/* #else */
		"TX DMIC1", "MIC BIAS1",
		"TX DMIC2", "Digital Mic2",
		"TX DMIC2", "MIC BIAS1",
		"TX DMIC3", "Digital Mic3",
		//"TX DMIC3", "MIC BIAS1",
/* #else */
		"TX DMIC3", "MIC BIAS3",
		"TX DMIC4", "Digital Mic4",
		"TX DMIC4", "MIC BIAS4",
		"TX DMIC5", "Digital Mic5",
		"TX DMIC5", "MIC BIAS4",
		"IN1_HPHL", "HPHL_OUT",
		"IN2_HPHR", "HPHR_OUT",
		"IN3_AUX", "AUX_OUT",
		"HAP_IN", "PCM_OUT",
		/*"WSA SRC0_INP", "SRC0",
		"TX SWR_INPUT", "SWR_MIC0 SWR_DMIC_OUTPUT",
		"TX SWR_INPUT", "SWR_MIC1 SWR_DMIC_OUTPUT",
		"TX SWR_INPUT", "SWR_MIC2 SWR_DMIC_OUTPUT",
		"TX SWR_INPUT", "SWR_MIC3 SWR_DMIC_OUTPUT",
		"VA SWR_INPUT", "SWR_MIC0 SWR_DMIC_OUTPUT",
		"VA SWR_INPUT", "SWR_MIC1 SWR_DMIC_OUTPUT",
		"VA SWR_INPUT", "SWR_MIC2 SWR_DMIC_OUTPUT",
		"VA SWR_INPUT", "SWR_MIC3 SWR_DMIC_OUTPUT",
		"WSA_TX DEC0_INP", "TX DEC0 MUX",
		"WSA_TX DEC1_INP", "TX DEC1 MUX",*/
		"RX_TX DEC0_INP", "TX DEC0 MUX",
		"RX_TX DEC1_INP", "TX DEC1 MUX",
		"RX_TX DEC2_INP", "TX DEC2 MUX",
		"RX_TX DEC3_INP", "TX DEC3 MUX",
		/*"SpkrLeft IN", "WSA_SPK1 OUT",
		"SpkrRight IN", "WSA_SPK2 OUT",*/
		"TX SWR_INPUT", "WCD_TX_OUTPUT",
		"VA SWR_INPUT", "VA_SWR_CLK",
		"VA SWR_INPUT", "WCD_TX_OUTPUT",
		"VA_AIF1 CAP", "VA_SWR_CLK",
		"VA_AIF2 CAP", "VA_SWR_CLK",
		"VA_AIF3 CAP", "VA_SWR_CLK",
		"VA DMIC0", "Digital Mic0",
		"VA DMIC1", "Digital Mic1",
		"VA DMIC2", "Digital Mic2",
		"VA DMIC3", "Digital Mic3",
		"VA DMIC4", "Digital Mic4",
		"VA DMIC5", "Digital Mic5",
		"VA DMIC0", "VA MIC BIAS3",
		//"VA DMIC1", "VA MIC BIAS3",
/* #else */
		"VA DMIC1", "VA MIC BIAS1",
		"VA DMIC2", "VA MIC BIAS1",
		//"VA DMIC3", "VA MIC BIAS1",
/* #else */
		"VA DMIC3", "VA MIC BIAS3",
		"VA DMIC4", "VA MIC BIAS4",
		"VA DMIC5", "VA MIC BIAS4";
	/*qcom,wsa-max-devs = <2>;*/
 /* #else */
	qcom,wsa-max-devs = <0>;

	qcom,tert-mi2s-gpios = <&cdc_tert_mi2s_gpios>;
	oplus,speaker-pa = "nxp";
	qcom,msm-mbhc-hs-mic-max-threshold-mv = <2600>;
	qcom,msm-mbhc-hs-mic-min-threshold-mv = <75>;

	qcom,msm-mbhc-usbc-audio-supported = <1>;
	qcom,msm-mbhc-hphl-swh = <1>;
	qcom,msm-mbhc-gnd-swh = <1>;
	oplus,mbhc-check-irq-en = <1>;
	oplus,mbhc-headset-micbias-alwayon = <1>;

	/* #ifdef OPLUS_FEATURE_4CH_AEC */
	qcom,afe-rxtx-lb = <1>;
	/* #endif OPLUS_FEATURE_4CH_AEC */
	fsa4480-i2c-handle = <&fsa4480_new>;
};

&qupv3_se13_i2c {
	fsa4480: fsa4480@42 {
		status = "disabled";
	};
};

&qupv3_se19_i2c {
	status = "ok";
	fsa4480_new: fsa4480_new@42 {
		compatible = "qcom,fsa4480-i2c";
		pinctrl-names = "default";
		pinctrl-0 = <&fsa_hs_det>;
		fsa4480,hs-det-gpio = <&tlmm 116 0x00>;
		reg = <0x42>;
	};
};

&tlmm {
	fsa_hs_det: fsa_hs_det  {
		mux {
			pins = "gpio116";
			function = "gpio";
		};

		config {
			pins = "gpio116";
			drive-strength = <2>;
			bias-disable;
			output-high;
		};
	};
};

&sde_dp {
	qcom,dp-aux-switch = <&fsa4480_new>;
};
&cdc_tert_mi2s_gpios {
	compatible = "qcom,msm-cdc-pinctrl";
	pinctrl-names = "aud_active", "aud_sleep";
	pinctrl-0 = <&tert_mi2s_sck_active &tert_mi2s_ws_active &tert_mi2s_sd0_active &tert_mi2s_sd1_active>;
	pinctrl-1 = <&tert_mi2s_sck_sleep &tert_mi2s_ws_sleep &tert_mi2s_sd0_sleep &tert_mi2s_sd1_sleep>;
};

&dai_mi2s2_tx {
	qcom,msm-mi2s-lines = <1>;
};

&dai_mi2s2_rx {
	qcom,msm-mi2s-lines = <2>;
};

/* #ifdef OPLUS_ARCH_EXTENDS */
&swr_dmic_01 {
	status = "disabled";
};

&swr_dmic_02 {
	status = "disabled";
};
&swr_dmic_03 {
	status = "disabled";
};
&swr_dmic_04 {
	status = "disabled";
};
/* #endif OPLUS_ARCH_EXTENDS */


//lahaina-mtp.dtsi

&tlmm {
	//#ifdef OPLUS_FEATRUE_ESIM
	esim_gpio: esim_gpio {
		mux {
			pins = "gpio6";
			function = "gpio";
		};
		config {
			pins = "gpio6";
			bias-disable; /* NO pull */
			drive-strength = <2>; /* 2 MA */
			output-high;
		};
	};

	esim_det_gpio: esim_det_gpio {
		mux {
			pins = "gpio47";
			function = "gpio";
		};
		config {
			pins = "gpio47";
			bias-disable; /* NO pull */
			drive-strength = <2>; /* 2 MA */
			output-high;
		};
	};
	//#endif /* OPLUS_FEATRUE_ESIM */
};

&pm8350_gpios {
	//#ifdef OPLUS_FEATRUE_DUAL_SIM_DETECT
	sim2_det_no_pull: sim2_det_no_pull {
			pins = "gpio8";
			function = "normal";
			input-enable;
			power-source = <1>;
			bias-disable;
	};

	sim2_det_pull_high: sim2_det_pull_high {
			pins = "gpio8";
			function = "normal";
			input-enable;
			power-source = <1>;
			bias-pull-up;
	};

	sim2_det_pull_low: sim2_det_pull_low {
			pins = "gpio8";
			function = "normal";
			input-enable;
			power-source = <1>;
			bias-pull-down;
	};
	//#endif OPLUS_FEATRUE_DUAL_SIM_DETECT
};

&soc {

    gpio_keys {
		compatible = "gpio-keys";
		label = "gpio-keys";

		pinctrl-names = "default";
		pinctrl-0 = <&key_vol_down_default>;
		// using volume down config update the default value
		vol_up {
			label = "volume_down";
			gpios = <&pm8350_gpios 6 GPIO_ACTIVE_LOW>;
			linux,input-type = <1>;
			linux,code = <KEY_VOLUMEDOWN>;
			gpio-key,wakeup;
			debounce-interval = <15>;
			linux,can-disable;
		};
	};

	qcom,qbt_handler {
		/delete-property/ qcom,ipc-gpio;
		//#ifdef OPLUS_FEATURE_FINGERPRINT
		status = "disabled";
		//#endif /*OPLUS_FEATURE_FINGERPRINT*/
	};

	extcon_usb1 {
		status = "disabled";
	};

	//#ifdef OPLUS_FEATRUE_ESIM
	oplus-gpio {
		compatible = "oplus,oplus-gpio";
		pinctrl-names = "default", "sim2_det_no_pull", "sim2_det_pull_high", "sim2_det_pull_low";
		pinctrl-0 = <&esim_gpio &esim_det_gpio &sim2_det_no_pull>;
		pinctrl-1 = <&sim2_det_no_pull>;
		pinctrl-2 = <&sim2_det_pull_high>;
		pinctrl-3 = <&sim2_det_pull_low>;
		oplus,oplus-gpio-esim = <&tlmm 6 0>;
		oplus,oplus-esim-det = <&tlmm 47 0>;
		oplus,oplus-sim2-det = <&pm8350_gpios 8 0>;
		oplus,uim-reset-pin = "modem_solution";
	};
	//#endif /* OPLUS_FEATRUE_ESIM */

	//#ifdef OPLUS_FEATRUE_SIM_HOLDER_DETECT
	oplus_sim_detect {
		compatible = "oplus, sim_detect";
		Hw,sim_det = "modem_det";
	};
	//#endif /* OPLUS_FEATRUE_SIM_HOLDER_DETECT */

	//#ifdef OPLUS_FEATURE_SENSOR_SMEM
	/*enum sensor_id { OPLUS_ACCEL,OPLUS_GYRO,OPLUS_MAG,OPLUS_LIGHT,OPLUS_PROXIMITY,OPLUS_SAR,OPLUS_CT,OPLUS_BAROMETER,SENSORS_NUM};*/
        sensor_fb: sensor_fb {
            compatible = "oplus,sensor-feedback";
            master-id  = <3>;
            smem-id    = <608>;
        };
	oplus_sensor {
		compatible = "oplus,sensor-devinfo";
		als-row-coe = <110>;
		/*enum {LSM6DSM = 0x01, BMI160 = 0x02, LSM6DS3 = 0x04, BMI260 = 0x08, LSM6DSO = 0x10,ICM4X6XX = 0x20};*/
		gsensor@0 {
			sensor-name = <0x20>;//ICM4X6XX
			sensor-direction = <6>;
			sensor-index = <0>;//source num
			sensor-type = <0>;//OPLUS_ACCEL
			use-sois = <1>;
		};
		/* enum {AKM0991X = 0x01, MMC5x3x = 0x02};*/
		msensor@0 {
			sensor-name = <0x2>;//MMC5x3x
			sensor-direction = <2>; //x=-x,y=-y,z=z
			sensor-index = <0>;
			sensor-type = <2>;//OPLUS_MAG
			parameter-number= <18>;
			soft-mag-parameter = <9999 0 129 1 45 1 466 0 10251 0 266 0 32 0 128 1 11396 0>;//e00 sign e01 sign...
		};
		/*enum {STK3A5X=0x01,TCS3701=0x02,TCS3408=0x04,MN78911=0x10};*/
        lsensor@0 {
            sensor-name = <0x10>;//MN78911
            sensor-index = <0>;//source num
            sensor-type = <3>;//LIGHT
            bus-number = <1>;
            irq-number = <89>;
            als-type = <1>;//<1-normal;2-under screen;3-normal needed compensation>
            is-unit-device = <1>;//<1-alsps unit device;0-separate device>
            is-als-dri = <0>;//<0-polling 1-irq>
            als-factor = <110>;
            is_als_initialed = <0>;
            als_buffer_length = <10>;
        };
        psensor@0 {
            sensor-name = <0x10>;//MN78911
            sensor-index = <0>;//source num
            sensor-type = <4>;//PROXIMITY
            bus-number = <1>;
            irq-number = <89>;
            ps-type = <1>;
            is_need_close_pd = <0>; /*1-need close 2-close has contidition 0-not close*/
            low_step = <300>;
            high_step = <400>;
            low_limit = <700>;
            high_limit = <900>;
            dirty_low_step = <500>;
            dirty_high_step = <700>;
            ps_dirty_limit = <1800>;
            ps_ir_limit = <2000>;
            ps_adjust_min = <0>;
            ps_adjust_max = <1850>;
            sampling_count = <5>;
            step_max = <400>;
            step_min = <100>;
            step_div = <2000>;
            anti_shake_delta = <70>;
            dynamic_cali_max = <4500>;
            raw2offset_radio = <1000>;
            offset_max = <60000>;
            offset_range_min = <0>;
            offset_range_max = <65534>;
            force_cali_limit = <2000>;
            cali_jitter_limit = <30>;
            cal_offset_margin = <3000>;//use to limit offset max
        };
        /* enum {SX9324 = 0x01, SX9331 = 0x02} */
        ssensor@0 {
            sensor-name = <0x2>;//SX9331
            sensor-index = <0>;
            sensor-type = <5>;//OPLUS_SAR
            irq-number = <91>;
            channel-num = <3>;
            is-dc-offset = <1>;
            dc-offset = <1 2 3 4 5 30001 30002 30003 30004 30005>;
        };
        /* enum {tcs3408 = 0x01  stk37600 = 0x02} */
        cctrsensor@0 {
            decoupled-driver = <1>; //0 - tcs3408 driver; 1 - oplus_cct driver
            sensor-name = <0x1>; //tcs3408
            sensor-index = <0>;
            sensor-type = <7>; //OPLUS_CCT_REAR
            bus-number = <5>;
            publish-sensors = <0x7>; //bit[0] - als, bit[1] - rgb, bit[2] - flicker
            para-matrix = <3>;//feature, 0-default
            is-ch-dri = <0>;
            timer-size = <25>; //ms
            fac-cali-sensor = <0x2>; //0x1 - als, 0x2 - rgb, 0x4 - flicker
        };

		/*virtual sensor
		enum sensor_algo_id {
			OPLUS_PICKUP_DETECT,
			OPLUS_LUX_AOD,
			OPLUS_TP_GESTURE,
			OPLUS_FP_DISPLAY,
			OPLUS_FREE_FALL,
			OPLUS_CAMERA_PROTECT,
			SENSOR_ALGO_NUM
		}*/
		pickup_detect {
			sensor-type = <0>;//OPLUS_PICKUP_DETECT
			is-virtual-sensor;
			is-need-prox = <1>;
			prox-type = <0>;
		};
		lux_aod {
			sensor-type = <1>; //OPLUS_LUX_AOD
			is-virtual-sensor;
			thrd-low = <12>;
			thrd-high = <50>;
			als-type = <0>; // 0 - ambient_light; 1 - wise_light
		};
		fp_display {
			sensor-type = <3>;//OPLUS_FP_DISPLAY
			is-virtual-sensor;
			prox-type = <0>; // 0 - proximity; 1 - proximity_fake
		};
		free_fall {
			sensor-type = <4>;//OPLUS_FREE_FALL
			is-virtual-sensor;
		};
	};
	//#endif /*OPLUS_FEATURE_SENSOR_SMEM*/

	//#ifdef OPLUS_FEATURE_FINGERPRINT
	oplus_secure_common {
		compatible = "oplus,secure_common";
		oplus,sec_reg_num = <0x780668>;
		oplus,sec_en_anti_reg = <0x7801CC>;
		oplus,sec_override1_reg = <0x7860C0>;
		oplus,override1_en_value = <0x1>;
	};
	//#endif /*OPLUS_FEATURE_FINGERPRINT*/

	//#ifdef OPLUS_FEATURE_FINGERPRINT
	oplus_fp_common {
		compatible = "oplus,fp_common";
		oplus,fp_gpio_num = <1>;
		oplus,fp_gpio_0 = <&tlmm 119 0x0>;
		pinctrl-names = "default";
		pinctrl-0 = <&gpio_id2_default>;
		goodix_optical_G3S {
			oplus,fp-id = <1>; /* fp id mapping table */
			vendor-chip = <11>; /* please refer to the struct fp_vendor_t in oplus_fp_commmon.n */
			eng-menu = "-1,-1"; /* represents SNR, inclination test item in engineer menu, and 0/1 means off/on */
			chip-name = "G_OPTICAL_G3S";  /* /proc/fp_id, will be displayed in engineer menu  */
		};
                jiiov_0302 {
			oplus,fp-id = <0>; /* fp id mapping table */
			vendor-chip = <23>; /* please refer to the struct fp_vendor_t in oplus_fp_commmon.n */
			eng-menu = "-1,-1"; /* represents SNR, inclination test item in engineer menu, and 0/1 means off/on */
			chip-name = "JIIOV_0302";  /* /proc/fp_id, will be displayed in engineer menu  */
		};
	};
	goodix_fp {
		status = "ok";
		compatible = "goodix,goodix_fp";
		interrupt-parent = <&tlmm>;
		interrupts = <38 0>;
		ldo-supply = <&L3C>;
		ldo-config = <3000000 3000000 150000>;
		goodix,gpio_irq = <&tlmm 38 0x1>;
		goodix,gpio_reset = <&tlmm 28 0x0>;
		pinctrl-names = "default";
		pinctrl-0 = <&gpio_goodix_irq_default>;
		notify_tpinfo_flag = <1>;
		power-num = <1>;
		power_source_1 {
			power-mode = <1>;
			power-name = "ldo";
			power-config = "ldo-config";
			delay-time = <0>;
		};
		};
	jiiov_fp {
		status = "ok";
		compatible = "jiiov,fingerprint";
		interrupt-parent = <&tlmm>;
		interrupts = <38 0x0>;
		anc,gpio_irq = <&tlmm 38 0x1>;
		anc,gpio_rst = <&tlmm 28 0x0>;
		ldo-supply = <&L3C>;
		pinctrl-names = "anc_reset_reset", "anc_reset_active", "anc_irq_active";
		pinctrl-0 = <&gpio_anc_reset_reset>;
		pinctrl-1 = <&gpio_anc_reset_active>;
		pinctrl-2 = <&gpio_anc_irq_active>;
	};
	//#endif /*OPLUS_FEATURE_FINGERPRINT*/
};

&qupv3_se4_i2c {
	status = "okay";
	/delete-property/ qcom,i2c-touch-active;

	st_fts@49 {
		status = "disabled";
	};
	focaltech@38 {
		status = "okay";
		compatible = "focaltech,ft3658u";
		reg = <0x38>;
		chip-name = "FT3658U";

		/* Power Config */
		vdd_2v8-supply = <&L11C>;
		vcc_1v8-supply = <&L12C>;
		vdd_2v8_volt = <3008000>;

		/* Interrupt && Irq-gpio */
		/* Other HW Resource */
		irq-gpio = <&tlmm 23 0x2002>;
		reset-gpio = <&tlmm 22 0x1>;
		pinctrl-names = "default";
		pinctrl-0 = <&ts_int_active &ts_reset_active>;

		touchpanel,max-num-support = <10>;
		touchpanel,tx-rx-num = <16 35>;
		touchpanel,panel-coords = <8640 19200>;
		touchpanel,display-coords = <1080 2400>;
		touchpanel,touchmajor-limit = <0 54>;
		touchpanel,smooth-level = <255 15 40 80 160 240>;
		touchpanel,sensitive-level = <255 30 25 20 15 8>;
		tp_type = <8>;
		panel_type = <8>;
		firmware_name = "AA231SF";
		platform_support_project = <21617 0x216B2 0x216B3 21147>;
		platform_support_project_dir = <21617 21617 21617 21147>;
		platform_support_project_commandline = "default_commandline","default_commandline","default_commandline","default_commandline";
		panel = <&dsi_oplus21617samsung_ams662zs01_1080_2400_cmd_dvt>;
		/* SW Support Feature Control */
		project_id = <21617>;
		irq_need_dev_resume_ok;
		black_gesture_support;
		fw_edge_limit_support;
		pressure_report_support;
		charger_pump_support;
		game_switch_support;
		touchpanel,high-frame-rate-time = <20>;
		switch_game_rate_support;
		report_rate_game_value = <1>;
		smart_gesture_support;
		headset_pump_support;
		fw_update_app_support;
		black_gesture_indep_support;
		sportify_aod_gesture_support;
		fingerprint_underscreen_support;
                health_monitor_support;
		exception_upload_support;
		//esd_handle_support;
		new_set_irq_wake_support;
		// focalt x8 resolution config
		high_resolution_support;
		high_resolution_support_x8;
		touchpanel,button-type = <4>;
		touchpanel.button-TRx = <0 0>;
		disable_suspend_irq_handler_support;
	};

	mtp_19065:s6sy791_19065@48 {
		compatible = "sec-s6sy791";
		reg = <0x48>;
		chip-name = "S6SY791";

		/* Interrupt && Irq-gpio */
		interrupt-parent = <&tlmm>;
		interrupts = <23 0x2008>;

		/* Power Config */
		//enable2v8_gpio = <&tlmm 26 0x1>;
		//enable1v8_gpio = <&tlmm 6 0x1>;
		vdd_2v8-supply = <&L3C>;
		vcc_1v8-supply = <&L6C>;
		vdd_2v8_volt = <3008000>;

		/* Other HW Resource */
		irq-gpio = <&tlmm 23 0x2008>;
		reset-gpio = <&tlmm 22 0x1>;
		pinctrl-names = "default";
		pinctrl-0 = <&ts_int_active &ts_reset_active>;

		touchpanel,max-num-support = <10>;
		touchpanel,tx-rx-num = <17 38>;
		earsense,tx-rx-num = <17 18>;
		touchpanel,panel-coords = <1440 3168>;
		touchpanel,display-coords = <1440 3168>;
		touchpanel,touchmajor-limit = <32 54>;
		project_id = <19065>;

		vid_len = <2>;
		panel_type = <8>;
		// type of tp_dev ,TP-SAMSUNG = 8;
		platform_support_project = <20627>;
		platform_support_project_dir = <20627>;
		platform_support_project_commandline = "mdss_dsi_oplus19065_samsung_1440_3168_dsc_cmd";
		platform_support_project_external_name = "BD368";

		touchpanel,elimination-range = <20 200 200>;
		prevention,no_handle_para = <0 0 0>;
		prevention,dead_area_width = <20 10>;
		prevention,makeup_cnt_weight = <4 1 2 2 1>;
		prevention,large_judge_para = <18 40 40>;
		prevention,large_corner_judge_para = <60 0 0 0 0 0>;
		prevention,condition_judge_para = <60 0>;
		prevention,condition_area_width = <60 30 100 100>;
		prevention,large_area_width = <70 100>;
		prevention,large_corner_width = <100 200 0>;
		prevention,eli_area_width = <120 500 250 120>;
		prevention,grip_disable_level = <4>;
		prevention,grip_handle_in_fw;

		algorithm_stretch_cfg = <0 0 0 0 0
					 50 20 1 3068 3168
					 0 0 0 0 0
					 0 0 0 0 0>;
		algorithm_support;
		kalman_value = <2000 500 256 1024 0x10001>;

		/* SW Support Feature Control */
		//ear_sense_support;
		black_gesture_support;
		//fw_edge_limit_support;
		charger_pump_support;
		//spurious_fingerprint_support;
		fw_update_app_support;
		smart_gesture_support;
		game_switch_support;
		kernel_grip_support;
		fingerprint_underscreen_support;
		headset_pump_support;
		pressure_report_support;
		irq_need_dev_resume_ok;
		report_rate_white_list_support;

		/*
		 *Virtual Key Config:
		 *1:touchpanel,button-type: <virtualkey_type  supportted_button-map>
		 *virtualkey_type:
		 *Type 1: using board_properties
		 *Type 2: using same IC (button zone&& touch zone are seprate)
		 *Type 3: using diffrent IC (button zone&& touch zone are seprate)
		 *Type 4: No need of virtual key process
		 *supportted_button-map:select|menu|home|back
		 *
		 *2:touchpanel,button-map
		 *type (X1,Y1)(X2,Y2)(X3,Y3)(Width_X,Hight_Y)--Only when button-type is 0
		 */
		touchpanel,button-type = <4>;
		touchpanel.button-TRx = <0 0>;
	};

	mtp_20627:synaptics20627@4B {
		compatible = "synaptics-s3908";
		reg = <0x4B>;
		chip-name = "S3908";

		/* Interrupt && Irq-gpio */
		interrupt-parent = <&tlmm>;
		interrupts = <23 0x2008>;

		/* Power Config */
		//enable2v8_gpio = <&tlmm 26 0x1>;
		//enable1v8_gpio = <&tlmm 6 0x1>;
		vdd_2v8-supply = <&L3C>;
		vcc_1v8-supply = <&L6C>;
		vdd_2v8_volt = <3008000>;

		/* Other HW Resource */
		irq-gpio = <&tlmm 23 0x2008>;
		reset-gpio = <&tlmm 22 0x1>;
		pinctrl-names = "default";
		pinctrl-0 = <&ts_int_active &ts_reset_active>;

		touchpanel,max-num-support = <10>;
		touchpanel,tx-rx-num = <17 38>;
		earsense,tx-rx-num = <17 18>;
		touchpanel,panel-coords = <5760 12864>;
		touchpanel,display-coords = <1440 3216>;
		touchpanel,touchmajor-limit = <256 256>;
		touchpanel,int-mode = <1>; /*0: interrupt and disable, 1:interrupt and not disable*/
		touchpanel,curved-size = <45>;

		touchpanel,elimination-range = <20 200 200>;
		prevention,no_handle_para = <0 0 0>;
		prevention,dead_area_width = <20 35338>;
		prevention,makeup_cnt_weight = <4 1 2 2 1>;
		prevention,large_judge_para = <18 135 135>;
		prevention,large_corner_judge_para = <25 0 0 0 0 0>;
		prevention,condition_judge_para = <20 0>;
		prevention,condition_area_width = <60 15380 100 100>;
		prevention,large_area_width = <45618 48188>;
		prevention,large_corner_width = <240 360 0>;
		prevention,eli_area_width = <0 0 0 0 0 0>;
		prevention,grip_disable_level = <6>;
		prevention,grip_handle_in_fw;
		prevention,dir_change_set_grip;

		touchpanel,smooth-level = <0 1 2 4 7 9>;
		touchpanel,smooth-level-charging = <0 2 4 7 8 9>;
		touchpanel,sensitive-level = <0 70 55 40 25 10>;
		touchpanel,single-optimized-time = <8>;

		end_stretch_value = <480 250 16 16>;

		touchpanel,tp_ic_type = <2>;
		panel_type = <8>;
		// type of tp_dev ,TP-SAMSUNG = 8;
		firmware_name = "SS";
		platform_support_project = <20627 20627>;
		platform_support_project_dir = <20627 20627>;
		platform_support_project_commandline = "mdss_dsi_oplus20031_samsung_1440_3216_dsc_cmd";

		/* SW Support Feature Control */
		black_gesture_support;
		//fw_edge_limit_support;
		pressure_report_support;
		charger_pump_support;
		game_switch_support;
		smart_gesture_support;
		fw_update_app_support;
		fingerprint_underscreen_support;
		freq_hop_simulate_support;
		report_flow_unlock_support;
		screenoff_fingerprint_info_support;
		irq_need_dev_resume_ok;
		//firmware_in_dts;
		enable_point_auto_change;
		report_rate_white_list_support;
		kernel_grip_support;
		grip_no_driver_support;
		health_monitor_support;
		black_gesture_indep_support;
		algorithm_support;

		/*
		 *Virtual Key Config:
		 *1:touchpanel,button-type: <virtualkey_type  supportted_button-map>
		 *virtualkey_type:
		 *Type 1: using board_properties
		 *Type 2: using same IC (button zone&& touch zone are seprate)
		 *Type 3: using diffrent IC (button zone&& touch zone are seprate)
		 *Type 4: No need of virtual key process
		 *supportted_button-map:select|menu|home|back
		 *
		 *2:touchpanel,button-map
		 *type (X1,Y1)(X2,Y2)(X3,Y3)(Width_X,Hight_Y)--Only when button-type is 0
		 */
		touchpanel,button-type = <4>;
		touchpanel.button-TRx = <0 0>;

		S3908 {
			report_rate_default = <60>;
			report_rate_game_value = <2>;
			default_gesture_mask = <8191>;
		};
	};

};


&sdhc_2 {
//	status = "ok";
//#else
	status = "disabled";
//#endif
};

&thermal_zones {
	tof-therm-usr {
		status = "disabled";
	};
};
//#endif

&pm8350b_haptics {
	status = "ok";
//#ifdef OPLUS_FEATURE_CHG_BASIC
	qcom,vmax-mv = <1280>;
	qcom,cl-vmax-mv = <1280>;
	qcom,lra-period-us = <5882>;
	qcom,fifo-vmax-mv = <9100>;
	qcom,old-steady-vmax-mv = <9100>;
	qcom,cal-data-restore;
//#endif
	qcom,vibrator-type = <809>;
};


&usb1 {
	/delete-property/ extcon;
	status = "disabled";
	dwc3@a800000 {
		status = "disabled";
	};

//#endif
};

//#ifdef OPLUS_FEATURE_FINGERPRINT
&removed_mem {
	no-map;
	//reg = <0x0 0xd8800000 0x0 0x9800000>;
	reg = <0x0 0xd8800000 0x0 0x8e00000>;
};
&splash_memory {
	//reg = <0x0 0xe5700000 0x0 0x02300000>;
	reg = <0x0 0xe4d00000 0x0 0x02300000>;
	label = "cont_splash_region";
};

&disp_rdump_memory {
	//reg = <0xe5700000 0x00800000>;
	reg = <0xe4d00000 0x00800000>;
	label = "disp_rdump_region";
};

&dfps_data_memory {
	//reg = <0x0 0xe7a00000 0x0 0x0100000>;
	reg = <0x0 0xe7000000 0x0 0x0100000>;
	label = "dfps_data_region";
};
//#endif /*OPLUS_FEATURE_FINGERPRINT*/

// #ifdef OPLUS_SYSTEM_UBOOT_LOG
// xbl_uefi_mem address get from boot_images Core.dsc.inc file: PcdEmbeddedFdBaseAddress + SERIAL_BUFFER_OFFSET,0x9FE00000+0x1F7000=0x9FFF7000
// kernel boot log: 0x9FE00000~ 0x9FFF7000
&reserved_memory {
		kboot_uboot_logmem: kboot_uboot_logmem@0x9FE00000 {
			reg = <0x0 0x9FE00000 0x0 0x200000>;
			compatible = "oplus,xbl_uefi_kbootlog";
			xbluefi-offset = <0x1F7000>;
			no-map;
		};
//#if IS_ENABLED(CONFIG_OPLUS_FEATURE_DUMP_DEVICE_INFO)
    ramoops: ramoops@0xE9700000 {
        compatible = "ramoops";
        reg = <0 0xE9700000 0 0x05B8000>; //5M + 736k
        record-size =  <0x40000>; //256k
        console-size = <0x40000>; //256k
        ftrace-size =  <0x200000>; //2M
        pmsg-size=     <0x200000>; //2M
        devinfo-size=  <0x08000>;  //32k
        dumpinfo-size=  <0x08000>; //32k
        rsv01info-size=  <0x08000>; //32k
        rsv02info-size=  <0x08000>; //32k
        rsv03info-size=  <0x08000>; //32k
        rsv04info-size=  <0x08000>; //32k
        rsv05info-size=  <0x08000>; //32k
        ecc-size=      <0x0>;
    };
//#endif
};
// #endif

//#ifdef OPLUS_BUG_STABILITY
&wlan {
	use-nv-mac;
};
//#endif /* OPLUS_BUG_STABILITY */

&soc {
	devinfo {
		compatible = "oplus-devinfo";

		//pinctrl-names = "active", "sleep";
		//pinctrl-0 = <&hw_id_active>;
		//pinctrl-1 = <&hw_id_sleep>;

		io-channels= <&pmk8350_vadc PM8350_ADC7_GPIO1>;
		io-channel-names= "vph_pwr_voltage_sub";

		main-sub {
			compatible = "hw-match, main-sub";
			use_pmic_adc;
			adc_ranges = <0 80
					81 180
					181 300
					301 420
					421 550
					551 650
					651 760
					761 850
					851 950
					951 1050
					1051 1150
					1151 1300>;
			aboard-patterns = <1 1 1 1 1 1 1 1 1 3 3 3 3 3 3 3 3 3>;

			/*main board*/
			match-projects = <21617 21617 21617 21617 21617 21617 21617 21617 21617 21147 21147 21147 21147 21147 21147 21147 21147 21147>;

			/*rf type*/
			rf_match_support;
			rf-patterns = <0 1 2 3 4 5 6 7 8 0 1 2 3 4 5 6 7 8>;
		};
	};
	oplus_rf_cable {
		compatible = "oplus,rf_cable";
		interrupt-parent = <&tlmm>;
		rf_cable_support_num = <1>;
		rf,cable0-gpio = <&tlmm 99 0>;
		rf,cable-support-timer = <0>;
		pinctrl-names = "rf_cable_active";
		pinctrl-0 = <&rf_cable0_active>;
	};
};

//#ifdef OPLUS_FEATURE_CHG_BASIC
&usb0 {
	dwc3@a600000 {
		snps,usb2-lpm-disable;
	};
};
//#endif /* OPLUS_FEATURE_CHG_BASIC */

//#ifdef OPLUS_FEATURE_THERMAL
&thermal_zones {
	cpu-gold-0-0-step {
		polling-delay-passive = <10>;
		polling-delay = <0>;
		thermal-sensors = <&tsens0 7>;
		thermal-governor = "step_wise";
		trips {
			cg00_config: cg00-config {
				temperature = <80000>;
				hysteresis = <3000>;
				type = "passive";
			};
		};

		cooling-maps {
			cg00_cdev {
				trip = <&cg00_config>;
				cooling-device = <&CPU4 THERMAL_NO_LIMIT
							(THERMAL_MAX_LIMIT - 8)>;
			};
		};
	};

	cpu-gold-0-1-step {
		polling-delay-passive = <10>;
		polling-delay = <0>;
		thermal-sensors = <&tsens0 8>;
		thermal-governor = "step_wise";
		trips {
			cg01_config: cg01-config {
				temperature = <80000>;
				hysteresis = <3000>;
				type = "passive";
			};
		};

		cooling-maps {
			cg01_cdev {
				trip = <&cg01_config>;
				cooling-device = <&CPU4 THERMAL_NO_LIMIT
							(THERMAL_MAX_LIMIT - 8)>;
			};
		};
	};

	cpu-gold-1-0-step {
		polling-delay-passive = <10>;
		polling-delay = <0>;
		thermal-sensors = <&tsens0 9>;
		thermal-governor = "step_wise";
		trips {
			cg10_config: cg10-config {
				temperature = <80000>;
				hysteresis = <3000>;
				type = "passive";
			};
		};

		cooling-maps {
			cg10_cdev {
				trip = <&cg10_config>;
				cooling-device = <&CPU5 THERMAL_NO_LIMIT
							(THERMAL_MAX_LIMIT - 8)>;
			};
		};
	};

	cpu-gold-1-1-step {
		polling-delay-passive = <10>;
		polling-delay = <0>;
		thermal-sensors = <&tsens0 10>;
		thermal-governor = "step_wise";
		trips {
			cg11_config: cg11-config {
				temperature = <80000>;
				hysteresis = <3000>;
				type = "passive";
			};
		};

		cooling-maps {
			cg11_cdev {
				trip = <&cg11_config>;
				cooling-device = <&CPU4 THERMAL_NO_LIMIT
							(THERMAL_MAX_LIMIT - 8)>;
			};
		};
	};

	cpu-gold-2-0-step {
		polling-delay-passive = <10>;
		polling-delay = <0>;
		thermal-sensors = <&tsens0 11>;
		thermal-governor = "step_wise";
		trips {
			cg20_config: cg20-config {
				temperature = <80000>;
				hysteresis = <3000>;
				type = "passive";
			};
		};

		cooling-maps {
			cg20_cdev {
				trip = <&cg20_config>;
				cooling-device = <&CPU4 THERMAL_NO_LIMIT
							(THERMAL_MAX_LIMIT - 8)>;
			};
		};
	};

	cpu-gold-2-1-step {
		polling-delay-passive = <10>;
		polling-delay = <0>;
		thermal-sensors = <&tsens0 12>;
		thermal-governor = "step_wise";
		trips {
			cg21_config: cg21-config {
				temperature = <80000>;
				hysteresis = <3000>;
				type = "passive";
			};
		};

		cooling-maps {
			cg21_cdev {
				trip = <&cg21_config>;
				cooling-device = <&CPU4 THERMAL_NO_LIMIT
							(THERMAL_MAX_LIMIT - 8)>;
			};
		};
	};

	cpu-gold-3-0-step {
		polling-delay-passive = <10>;
		polling-delay = <0>;
		thermal-sensors = <&tsens0 13>;
		thermal-governor = "step_wise";
		trips {
			cg30_config: cg30-config {
				temperature = <80000>;
				hysteresis = <3000>;
				type = "passive";
			};
		};

		cooling-maps {
			cg30_cdev {
				trip = <&cg30_config>;
				cooling-device = <&CPU7 THERMAL_NO_LIMIT
							(THERMAL_MAX_LIMIT - 8)>;
			};
		};
	};

	cpu-gold-3-1-step {
		polling-delay-passive = <10>;
		polling-delay = <0>;
		thermal-sensors = <&tsens0 14>;
		thermal-governor = "step_wise";
		trips {
			cg31_config: cg31-config {
				temperature = <80000>;
				hysteresis = <3000>;
				type = "passive";
			};
		};

		cooling-maps {
			cg31_cdev {
				trip = <&cg31_config>;
				cooling-device = <&CPU7 THERMAL_NO_LIMIT
							(THERMAL_MAX_LIMIT - 8)>;
			};
		};
	};
};
//#endif OPLUS_FEATURE_THERMAL

//ifdef OPLUS_BUG_STABILITY
&L6C {
		regulator-max-microvolt = <1800000>;
		qcom,init-voltage = <1800000>;
		qcom,proxy-consumer-enable;
		qcom,proxy-consumer-current = <243000>;
};

&soc {
	dsi_panel_pwr_supply_21147: dsi_panel_pwr_supply_21147 {
		#address-cells = <1>;
		#size-cells = <0>;

		qcom,panel-supply-entry@0 {
			reg = <0>;
			qcom,supply-name = "vddio";
			qcom,supply-min-voltage = <1800000>;
			qcom,supply-max-voltage = <1800000>;
			qcom,supply-enable-load = <60700>;
			qcom,supply-disable-load = <80>;
			qcom,supply-post-on-sleep = <0>;
		};

		qcom,panel-supply-entry@1 {
			reg = <1>;
			qcom,supply-name = "vdd";
			qcom,supply-min-voltage = <3000000>;
			qcom,supply-max-voltage = <3000000>;
			qcom,supply-enable-load = <10000>;
			qcom,supply-disable-load = <0>;
			qcom,supply-post-on-sleep = <0>;
		};
	};
};


#include "dsi-panel-oplus21147-samsung-ams662zs01-1080-2400-dvt-dsc-cmd.dtsi"
#include "dsi-panel-oplus21147-samsung-ams662zs01-1080-2400-rev-dsc-cmd.dtsi"

&mdss_dsi_phy1 {
		qcom,platform-strength-ctrl = [FF 03
						FF 03
						FF 03
						FF 03
						FF 00];
		qcom,platform-lane-config = [00 00 88 0a
						00 00 88 0a
						00 00 88 0a
						00 00 88 0a
						00 00 88 8a];
	};

&mdss_dsi_phy0 {
	/delete-property/ qcom,dsi-pll-ssc-en;
	/delete-property/ qcom,dsi-pll-ssc-mode;
	oplus,disable-ssc;
};

&mdss_dsi_phy1 {
	/delete-property/ qcom,dsi-pll-ssc-en;
	/delete-property/ qcom,dsi-pll-ssc-mode;
	oplus,disable-ssc;
};

&sde_dsi {
		vddio-supply = <&L6C>;
		qcom,dsi-default-panel = <&dsi_oplus21617samsung_ams662zs01_1080_2400_cmd_dvt>;
	};

//#endif

&tlmm {
	pm8010j_active: pm8010j_active {
		mux {
			pins = "gpio33";
			function = "gpio";
		};

		config {
			pins = "gpio33";
			bias-disable;
			output-high;
			drive-strength = <2>;
		};
	};
};

&qupv3_se13_i2c {
	pm8008j@c {
		status = "disabled";
	};

	pm8008j@d {
		status = "disabled";
	};

	pm8008i@8 {
		status = "disabled";
	};

	pm8008i@9 {
		status = "disabled";
	};
};

&qupv3_se13_i2c {
    #address-cells = <1>;
    #size-cells = <0>;
    status = "ok";
    qcom,clk-freq-out = <100000>;

    pm8010j@8 {
        compatible = "qcom,i2c-pmic";
        reg = <0x8>;
        #address-cells = <1>;
        #size-cells = <0>;

        pinctrl-names = "default";
        pinctrl-0 = <&pm8010j_active>;

        pm8010-chip@900 {
            compatible = "qcom,pm8008-chip";
            reg = <0x900>;

            PM8010J_EN: qcom,pm8008-chip-en {
                regulator-name = "pm8010j-chip-en";
            };
        };

        qcom,revid@100 {
            compatible = "qcom,qpnp-revid";
            reg = <0x100>;
        };
    };

    pm8010j@9 {
        compatible = "qcom,i2c-pmic";
        reg = <0x9>;
        #address-cells = <1>;
        #size-cells = <0>;

        qcom,pm8010j-regulator {
            compatible = "qcom,pm8010-regulator";
            #address-cells = <1>;
            #size-cells = <0>;

            pm8008_en-supply = <&PM8010J_EN>;
            vdd_l1_l2-supply = <&S12B>;
            vdd_l3_l4-supply = <&BOB>;
            vdd_l5-supply = <&S1C>;
            vdd_l6-supply = <&BOB>;
            vdd_l7-supply = <&BOB>;

            pm8010j_l1: regulator@4000 {
                reg = <0x4000>;
                regulator-name = "pm8010j_l1";
                regulator-min-microvolt = <1000000>;
                regulator-max-microvolt = <1200000>;
                qcom,min-dropout-voltage = <100000>;
                qcom,hpm-min-load = <30000>;
            };

            pm8010j_l2: regulator@4100 {
                reg = <0x4100>;
                regulator-name = "pm8010j_l2";
                regulator-min-microvolt = <944000>;
                regulator-max-microvolt = <1152000>;
                qcom,min-dropout-voltage = <150000>;
                qcom,hpm-min-load = <30000>;
            };

            pm8010j_l3: regulator@4200 {
                reg = <0x4200>;
                regulator-name = "pm8010j_l3";
                regulator-min-microvolt = <2696000>;
                regulator-max-microvolt = <3000000>;
                qcom,min-dropout-voltage = <200000>;
            };

            pm8010j_l4: regulator@4300 {
                reg = <0x4300>;
                regulator-name = "pm8010j_l4";
                regulator-min-microvolt = <2696000>;
                regulator-max-microvolt = <2904000>;
                qcom,min-dropout-voltage = <200000>;
            };

            pm8010j_l5: regulator@4400 {
                reg = <0x4400>;
                regulator-name = "pm8010j_l5";
                regulator-min-microvolt = <1696000>;
                regulator-max-microvolt = <1800000>;
                qcom,min-dropout-voltage = <70000>;
            };

            pm8010j_l6: regulator@4500 {
                reg = <0x4500>;
                regulator-name = "pm8010j_l6";
                regulator-min-microvolt = <2696000>;
                regulator-max-microvolt = <2904000>;
                qcom,min-dropout-voltage = <200000>;
            };

            pm8010j_l7: regulator@4600 {
                reg = <0x4600>;
                regulator-name = "pm8010j_l7";
                regulator-min-microvolt = <2696000>;
                regulator-max-microvolt = <3000000>;
                qcom,min-dropout-voltage = <200000>;
            };
        };
    };
};

&i2c_freq_1Mhz_cci0 {
    hw-scl-stretch-en = <0>;
};

&i2c_freq_custom_cci0 {
    hw-scl-stretch-en = <0>;
};

&i2c_freq_400Khz_cci0 {
    hw-scl-stretch-en = <0>;
};
